# regs-internal register map
Registers are 32-bit, access not given, no defined reset value unless marked. A register's access mark holds for its fields unless they carry their own. Addresses are absolute; registers are grouped by the start of their names; [hi:lo] are bit positions.

## SC1
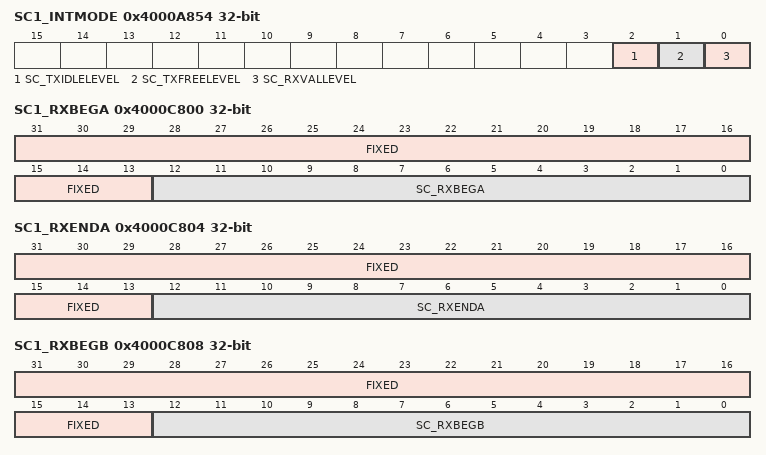
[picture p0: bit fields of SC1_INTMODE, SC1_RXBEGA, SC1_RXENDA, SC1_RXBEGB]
0x4000A854 SC1_INTMODE
  [2] SC_TXIDLELEVEL, [1] SC_TXFREELEVEL, [0] SC_RXVALLEVEL
0x4000C800 SC1_RXBEGA
  [31:13] FIXED, [12:0] SC_RXBEGA
0x4000C804 SC1_RXENDA
  [31:13] FIXED, [12:0] SC_RXENDA
0x4000C808 SC1_RXBEGB
  [31:13] FIXED, [12:0] SC_RXBEGB
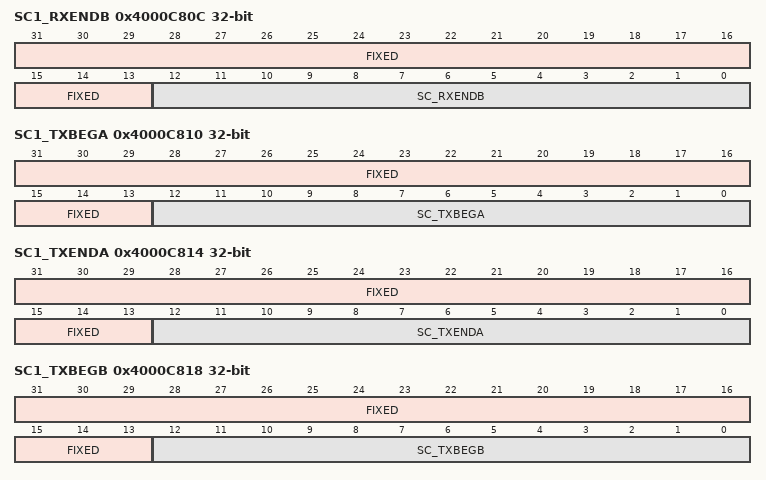
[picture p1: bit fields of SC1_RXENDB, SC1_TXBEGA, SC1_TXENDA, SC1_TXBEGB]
0x4000C80C SC1_RXENDB
  [31:13] FIXED, [12:0] SC_RXENDB
0x4000C810 SC1_TXBEGA
  [31:13] FIXED, [12:0] SC_TXBEGA
0x4000C814 SC1_TXENDA
  [31:13] FIXED, [12:0] SC_TXENDA
0x4000C818 SC1_TXBEGB
  [31:13] FIXED, [12:0] SC_TXBEGB
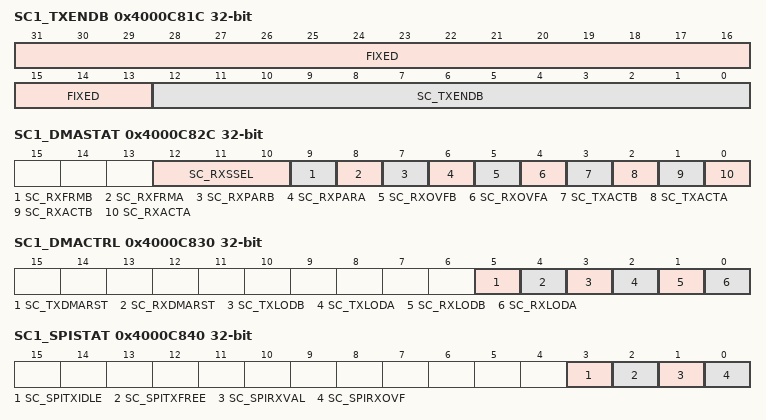
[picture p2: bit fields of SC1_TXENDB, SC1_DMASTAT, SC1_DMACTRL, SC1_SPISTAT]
0x4000C81C SC1_TXENDB
  [31:13] FIXED, [12:0] SC_TXENDB
0x4000C820 SC1_RXCNTA
  [12:0] SC_RXCNTA
0x4000C824 SC1_RXCNTB
  [12:0] SC_RXCNTB
0x4000C828 SC1_TXCNT
  [12:0] SC_TXCNT
0x4000C82C SC1_DMASTAT
  [12:10] SC_RXSSEL, [9] SC_RXFRMB, [8] SC_RXFRMA, [7] SC_RXPARB, [6] SC_RXPARA, [5] SC_RXOVFB, [4] SC_RXOVFA, [3] SC_TXACTB, [2] SC_TXACTA, [1] SC_RXACTB, [0] SC_RXACTA
0x4000C830 SC1_DMACTRL
  [5] SC_TXDMARST, [4] SC_RXDMARST, [3] SC_TXLODB, [2] SC_TXLODA, [1] SC_RXLODB, [0] SC_RXLODA
0x4000C834 SC1_RXERRA
  [12:0] SC_RXERRA
0x4000C838 SC1_RXERRB
  [12:0] SC_RXERRB
0x4000C83C SC1_DATA
  [7:0] SC_DATA
0x4000C840 SC1_SPISTAT
  [3] SC_SPITXIDLE, [2] SC_SPITXFREE, [1] SC_SPIRXVAL, [0] SC_SPIRXOVF
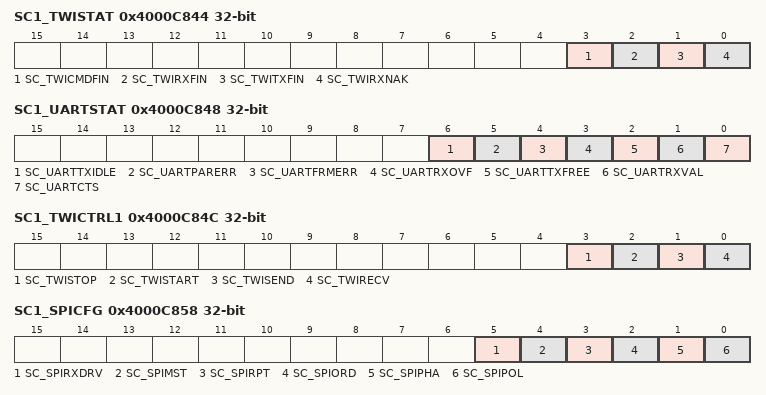
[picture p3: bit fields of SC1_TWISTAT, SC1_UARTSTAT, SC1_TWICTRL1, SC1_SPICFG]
0x4000C844 SC1_TWISTAT
  [3] SC_TWICMDFIN, [2] SC_TWIRXFIN, [1] SC_TWITXFIN, [0] SC_TWIRXNAK
0x4000C848 SC1_UARTSTAT
  [6] SC_UARTTXIDLE, [5] SC_UARTPARERR, [4] SC_UARTFRMERR, [3] SC_UARTRXOVF, [2] SC_UARTTXFREE, [1] SC_UARTRXVAL, [0] SC_UARTCTS
0x4000C84C SC1_TWICTRL1
  [3] SC_TWISTOP, [2] SC_TWISTART, [1] SC_TWISEND, [0] SC_TWIRECV
0x4000C850 SC1_TWICTRL2
  [0] SC_TWIACK
0x4000C854 SC1_MODE
  [1:0] SC_MODE
0x4000C858 SC1_SPICFG
  [5] SC_SPIRXDRV, [4] SC_SPIMST, [3] SC_SPIRPT, [2] SC_SPIORD, [1] SC_SPIPHA, [0] SC_SPIPOL
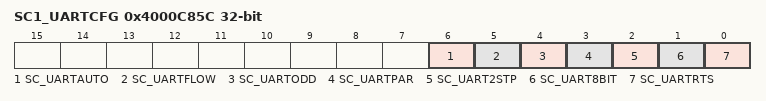
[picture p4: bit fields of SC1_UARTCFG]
0x4000C85C SC1_UARTCFG
  [6] SC_UARTAUTO, [5] SC_UARTFLOW, [4] SC_UARTODD, [3] SC_UARTPAR, [2] SC_UART2STP, [1] SC_UART8BIT, [0] SC_UARTRTS
0x4000C860 SC1_RATELIN
  [3:0] SC_RATELIN
0x4000C864 SC1_RATEEXP
  [3:0] SC_RATEEXP
0x4000C868 SC1_UARTPER
  [15:0] SC_UARTPER
0x4000C86C SC1_UARTFRAC
  [0] SC_UARTFRAC
0x4000C870 SC1_RXCNTSAVED
  [12:0] SC_RXCNTSAVED

## SC2
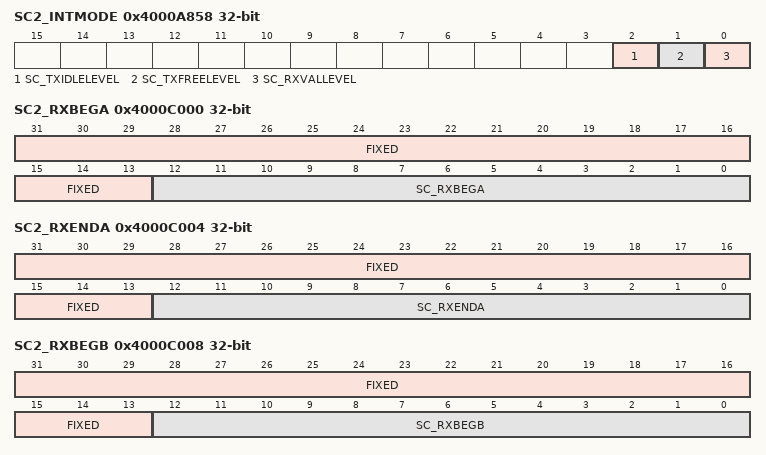
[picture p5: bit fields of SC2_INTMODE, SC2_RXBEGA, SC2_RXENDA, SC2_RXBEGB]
0x4000A858 SC2_INTMODE
  [2] SC_TXIDLELEVEL, [1] SC_TXFREELEVEL, [0] SC_RXVALLEVEL
0x4000C000 SC2_RXBEGA
  [31:13] FIXED, [12:0] SC_RXBEGA
0x4000C004 SC2_RXENDA
  [31:13] FIXED, [12:0] SC_RXENDA
0x4000C008 SC2_RXBEGB
  [31:13] FIXED, [12:0] SC_RXBEGB
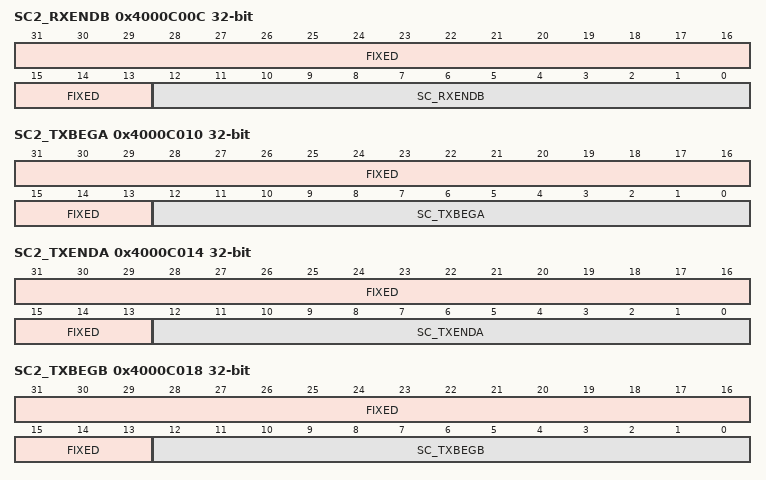
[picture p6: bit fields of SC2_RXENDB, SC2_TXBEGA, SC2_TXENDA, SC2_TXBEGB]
0x4000C00C SC2_RXENDB
  [31:13] FIXED, [12:0] SC_RXENDB
0x4000C010 SC2_TXBEGA
  [31:13] FIXED, [12:0] SC_TXBEGA
0x4000C014 SC2_TXENDA
  [31:13] FIXED, [12:0] SC_TXENDA
0x4000C018 SC2_TXBEGB
  [31:13] FIXED, [12:0] SC_TXBEGB
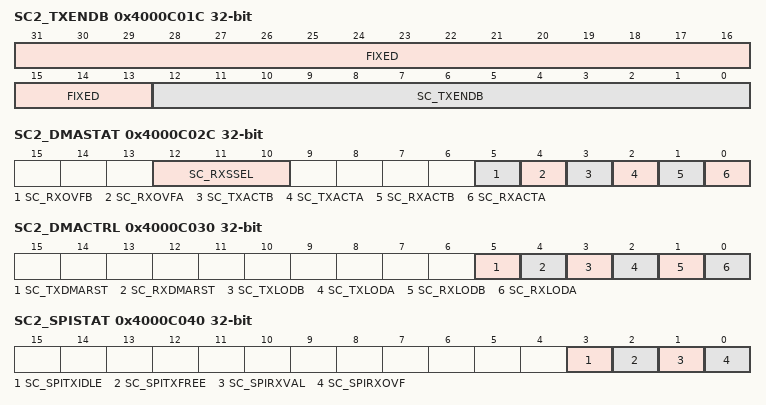
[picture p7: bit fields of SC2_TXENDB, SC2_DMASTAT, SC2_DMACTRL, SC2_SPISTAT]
0x4000C01C SC2_TXENDB
  [31:13] FIXED, [12:0] SC_TXENDB
0x4000C020 SC2_RXCNTA
  [12:0] SC_RXCNTA
0x4000C024 SC2_RXCNTB
  [12:0] SC_RXCNTB
0x4000C028 SC2_TXCNT
  [12:0] SC_TXCNT
0x4000C02C SC2_DMASTAT
  [12:10] SC_RXSSEL, [5] SC_RXOVFB, [4] SC_RXOVFA, [3] SC_TXACTB, [2] SC_TXACTA, [1] SC_RXACTB, [0] SC_RXACTA
0x4000C030 SC2_DMACTRL
  [5] SC_TXDMARST, [4] SC_RXDMARST, [3] SC_TXLODB, [2] SC_TXLODA, [1] SC_RXLODB, [0] SC_RXLODA
0x4000C034 SC2_RXERRA
  [12:0] SC_RXERRA
0x4000C038 SC2_RXERRB
  [12:0] SC_RXERRB
0x4000C03C SC2_DATA
  [7:0] SC_DATA
0x4000C040 SC2_SPISTAT
  [3] SC_SPITXIDLE, [2] SC_SPITXFREE, [1] SC_SPIRXVAL, [0] SC_SPIRXOVF
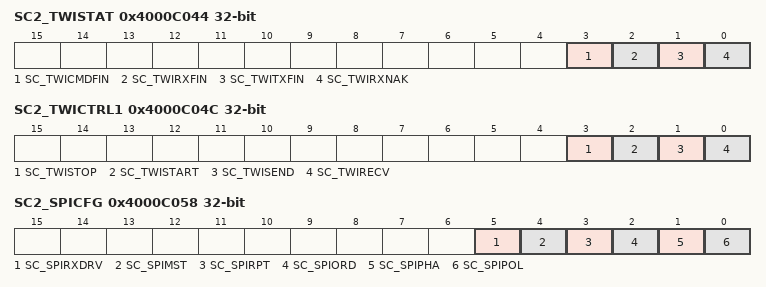
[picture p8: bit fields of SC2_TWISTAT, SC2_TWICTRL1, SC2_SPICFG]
0x4000C044 SC2_TWISTAT
  [3] SC_TWICMDFIN, [2] SC_TWIRXFIN, [1] SC_TWITXFIN, [0] SC_TWIRXNAK
0x4000C04C SC2_TWICTRL1
  [3] SC_TWISTOP, [2] SC_TWISTART, [1] SC_TWISEND, [0] SC_TWIRECV
0x4000C050 SC2_TWICTRL2
  [0] SC_TWIACK
0x4000C054 SC2_MODE
  [1:0] SC_MODE
0x4000C058 SC2_SPICFG
  [5] SC_SPIRXDRV, [4] SC_SPIMST, [3] SC_SPIRPT, [2] SC_SPIORD, [1] SC_SPIPHA, [0] SC_SPIPOL
0x4000C060 SC2_RATELIN
  [3:0] SC_RATELIN
0x4000C064 SC2_RATEEXP
  [3:0] SC_RATEEXP
0x4000C070 SC2_RXCNTSAVED
  [12:0] SC_RXCNTSAVED
